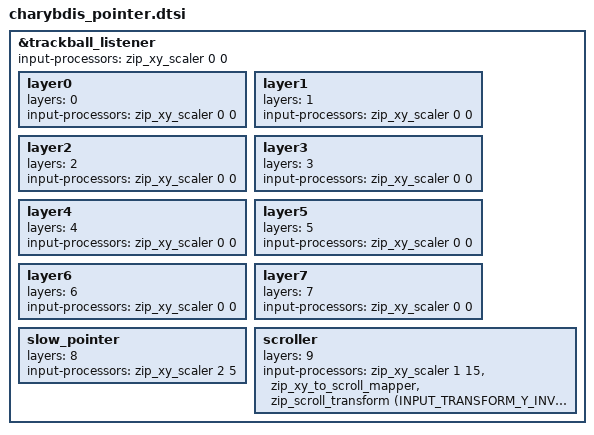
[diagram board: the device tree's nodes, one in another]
#include <input/processors.dtsi>
#include <dt-bindings/zmk/input_transform.h>

&trackball_listener {
    /* base processor chain on all layers */
    /*input-processors = <&zip_xy_scaler 5 5>, <&zip_temp_layer 7 300>;*/
    input-processors = <&zip_xy_scaler 0 0>;    

    layer0: layer0 {
        layers           = <0>;
        input-processors = <&zip_xy_scaler 0 0>;
    };

    layer1: layer1 {
        layers           = <1>;
        input-processors = <&zip_xy_scaler 0 0>;
    };

    layer2: layer2 {
        layers           = <2>;
        input-processors = <&zip_xy_scaler 0 0>;
    };

    layer3: layer3 {
        layers           = <3>;
        input-processors = <&zip_xy_scaler 0 0>;
    };

    layer4: layer4 {
        layers           = <4>;
        input-processors = <&zip_xy_scaler 0 0>;
    };

    layer5: layer5 {
        layers           = <5>;
        input-processors = <&zip_xy_scaler 0 0>;
    };
    
    layer6: layer6 {
        layers           = <6>;
        input-processors = <&zip_xy_scaler 0 0>;
    };

    layer7: layer7 {
        layers           = <7>;
        input-processors = <&zip_xy_scaler 0 0>;
    };

    /* slow-pointer override */
    slow_pointer: slow_pointer {
        layers           = <8>;
        input-processors = <&zip_xy_scaler 2 5>;
    };

    /* scroll override */
    scroller: scroller {
        layers           = <9>;
        input-processors = <
            &zip_xy_scaler 1 15                              // Scales the scroll speed
            &zip_xy_to_scroll_mapper                         // Converts XY movement to scroll events
            &zip_scroll_transform (INPUT_TRANSFORM_Y_INVERT) // Inverts the scroll direction
        >;
    };
};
